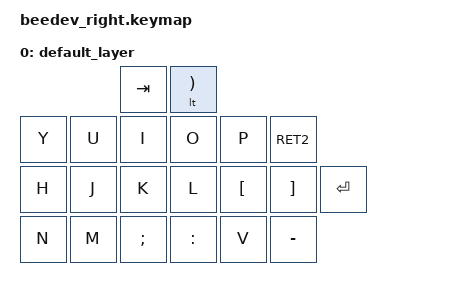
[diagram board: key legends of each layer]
#include <dt-bindings/zmk/keys.h>
#include <dt-bindings/zmk/bt.h>
#include <behaviors.dtsi>

/ {
    keymap{
        compatible = "zmk,keymap";

        default_layer {
            bindings = <
                                &kp TAB     &lt RIGHT_PARENTHESIS                                
                &kp Y   &kp U   &kp I       &kp O                   &kp P       &kp RET2         
                &kp H   &kp J   &kp K       &kp L                   &kp LBKT    &kp RBKT    &kp RET
                &kp N   &kp M   &kp SEMI    &kp COLON               &kp V       &kp MINUS        
            >;
        };
    };
};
